# CY8C5888LTI_LP097 register map
File version: 0.1
Registers are 8-bit, read-write, no defined reset value unless marked. A register's access mark holds for its fields unless they carry their own. Offsets are from the block's base; [hi:lo] are bit positions.

## I2Sthree
Base 0x00000000
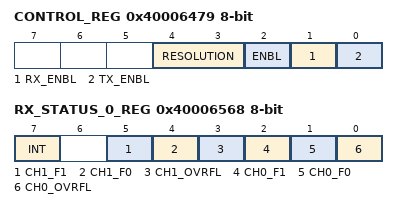
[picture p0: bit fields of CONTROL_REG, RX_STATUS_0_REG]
0x40006479 CONTROL_REG
  [4:3] RESOLUTION — Specifies data bits value. Applicable only if dynamic bit resolution is selected.
    0=Cy8_BIT; 1=Cy16_BIT; 2=Cy24_BIT; 3=Cy32_BIT
  [2] ENBL — Starts the generation of the WS and SCK outputs.
    1=ENABLED; 0=DISABLED
  [1] RX_ENBL — Enables Rx direction. Applicable only if Rx direction presents for the component.
    1=ENABLED; 0=DISABLED
  [0] TX_ENBL — Enables Tx direction. Applicable only if Tx direction presents for the component.
    1=ENABLED; 0=DISABLED
0x40006568 RX_STATUS_0_REG
  [7] INT ro — Interrupt bit
  [5] CH1_F1 ro — Stereo channel 1 FIFO 1 state
    0=EMPTY; 1=NOT_EMPTY
  [4] CH1_F0 ro — Stereo channel 1 FIFO 0 state
    0=EMPTY; 1=NOT_EMPTY
  [3] CH1_OVRFL ro — Stereo channel 1 FIFO overflow
    0=NO_OVERFLOW; 1=OVERFLOW
  [2] CH0_F1 ro — Stereo channel 0 FIFO 1 state
    0=EMPTY; 1=NOT_EMPTY
  [1] CH0_F0 ro — Stereo channel 0 FIFO 0 state
    0=EMPTY; 1=NOT_EMPTY
  [0] CH0_OVRFL ro — Stereo channel 0 FIFO overflow
    0=NO_OVERFLOW; 1=OVERFLOW

## I2Stwo
Base 0x00000000
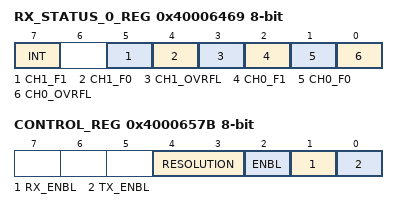
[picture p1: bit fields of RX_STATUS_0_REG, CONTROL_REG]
0x40006469 RX_STATUS_0_REG
  [7] INT ro — Interrupt bit
  [5] CH1_F1 ro — Stereo channel 1 FIFO 1 state
    0=EMPTY; 1=NOT_EMPTY
  [4] CH1_F0 ro — Stereo channel 1 FIFO 0 state
    0=EMPTY; 1=NOT_EMPTY
  [3] CH1_OVRFL ro — Stereo channel 1 FIFO overflow
    0=NO_OVERFLOW; 1=OVERFLOW
  [2] CH0_F1 ro — Stereo channel 0 FIFO 1 state
    0=EMPTY; 1=NOT_EMPTY
  [1] CH0_F0 ro — Stereo channel 0 FIFO 0 state
    0=EMPTY; 1=NOT_EMPTY
  [0] CH0_OVRFL ro — Stereo channel 0 FIFO overflow
    0=NO_OVERFLOW; 1=OVERFLOW
0x4000657B CONTROL_REG
  [4:3] RESOLUTION — Specifies data bits value. Applicable only if dynamic bit resolution is selected.
    0=Cy8_BIT; 1=Cy16_BIT; 2=Cy24_BIT; 3=Cy32_BIT
  [2] ENBL — Starts the generation of the WS and SCK outputs.
    1=ENABLED; 0=DISABLED
  [1] RX_ENBL — Enables Rx direction. Applicable only if Rx direction presents for the component.
    1=ENABLED; 0=DISABLED
  [0] TX_ENBL — Enables Tx direction. Applicable only if Tx direction presents for the component.
    1=ENABLED; 0=DISABLED

## I2Sfour
Base 0x00000000
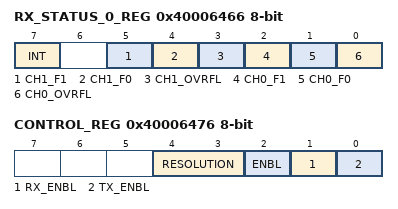
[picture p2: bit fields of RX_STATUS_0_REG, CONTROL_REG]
0x40006466 RX_STATUS_0_REG
  [7] INT ro — Interrupt bit
  [5] CH1_F1 ro — Stereo channel 1 FIFO 1 state
    0=EMPTY; 1=NOT_EMPTY
  [4] CH1_F0 ro — Stereo channel 1 FIFO 0 state
    0=EMPTY; 1=NOT_EMPTY
  [3] CH1_OVRFL ro — Stereo channel 1 FIFO overflow
    0=NO_OVERFLOW; 1=OVERFLOW
  [2] CH0_F1 ro — Stereo channel 0 FIFO 1 state
    0=EMPTY; 1=NOT_EMPTY
  [1] CH0_F0 ro — Stereo channel 0 FIFO 0 state
    0=EMPTY; 1=NOT_EMPTY
  [0] CH0_OVRFL ro — Stereo channel 0 FIFO overflow
    0=NO_OVERFLOW; 1=OVERFLOW
0x40006476 CONTROL_REG
  [4:3] RESOLUTION — Specifies data bits value. Applicable only if dynamic bit resolution is selected.
    0=Cy8_BIT; 1=Cy16_BIT; 2=Cy24_BIT; 3=Cy32_BIT
  [2] ENBL — Starts the generation of the WS and SCK outputs.
    1=ENABLED; 0=DISABLED
  [1] RX_ENBL — Enables Rx direction. Applicable only if Rx direction presents for the component.
    1=ENABLED; 0=DISABLED
  [0] TX_ENBL — Enables Tx direction. Applicable only if Tx direction presents for the component.
    1=ENABLED; 0=DISABLED

## I2Sone
Base 0x00000000
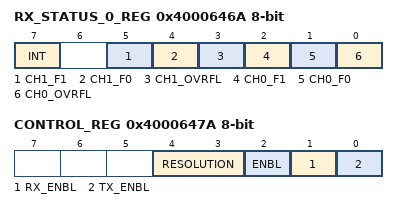
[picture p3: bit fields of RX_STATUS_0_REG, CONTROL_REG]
0x4000646A RX_STATUS_0_REG
  [7] INT ro — Interrupt bit
  [5] CH1_F1 ro — Stereo channel 1 FIFO 1 state
    0=EMPTY; 1=NOT_EMPTY
  [4] CH1_F0 ro — Stereo channel 1 FIFO 0 state
    0=EMPTY; 1=NOT_EMPTY
  [3] CH1_OVRFL ro — Stereo channel 1 FIFO overflow
    0=NO_OVERFLOW; 1=OVERFLOW
  [2] CH0_F1 ro — Stereo channel 0 FIFO 1 state
    0=EMPTY; 1=NOT_EMPTY
  [1] CH0_F0 ro — Stereo channel 0 FIFO 0 state
    0=EMPTY; 1=NOT_EMPTY
  [0] CH0_OVRFL ro — Stereo channel 0 FIFO overflow
    0=NO_OVERFLOW; 1=OVERFLOW
0x4000647A CONTROL_REG
  [4:3] RESOLUTION — Specifies data bits value. Applicable only if dynamic bit resolution is selected.
    0=Cy8_BIT; 1=Cy16_BIT; 2=Cy24_BIT; 3=Cy32_BIT
  [2] ENBL — Starts the generation of the WS and SCK outputs.
    1=ENABLED; 0=DISABLED
  [1] RX_ENBL — Enables Rx direction. Applicable only if Rx direction presents for the component.
    1=ENABLED; 0=DISABLED
  [0] TX_ENBL — Enables Tx direction. Applicable only if Tx direction presents for the component.
    1=ENABLED; 0=DISABLED
